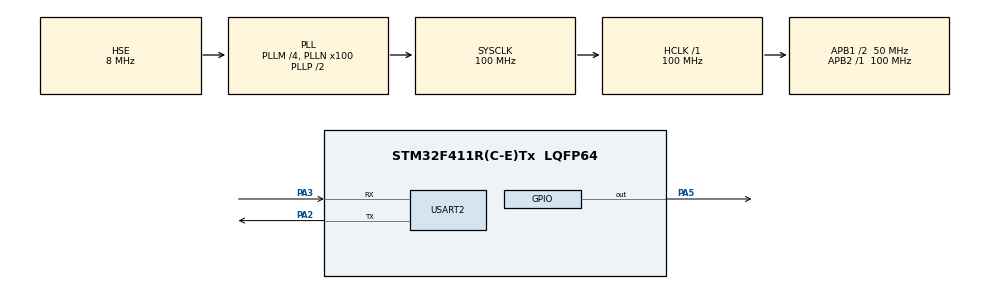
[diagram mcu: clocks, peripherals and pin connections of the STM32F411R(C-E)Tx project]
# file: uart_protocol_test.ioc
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Mcu.Family=STM32F4
Mcu.Name=STM32F411R(C-E)Tx
Mcu.Package=LQFP64
NVIC.PriorityGroup=NVIC_PRIORITYGROUP_4
NVIC.USART2_IRQn=true\:0\:0\:false\:false\:true\:true\:true\:true
PA13.Mode=Serial_Wire
PA13.Signal=SYS_JTMS-SWDIO
PA14.Mode=Serial_Wire
PA14.Signal=SYS_JTCK-SWCLK
PA2.Mode=Asynchronous
PA2.Signal=USART2_TX
PA3.Mode=Asynchronous
PA3.Signal=USART2_RX
PA5.Signal=GPIO_Output
PH0\ -\ OSC_IN.Mode=HSE-External-Oscillator
PH0\ -\ OSC_IN.Signal=RCC_OSC_IN
PH1\ -\ OSC_OUT.Mode=HSE-External-Oscillator
PH1\ -\ OSC_OUT.Signal=RCC_OSC_OUT
ProjectManager.HeapSize=0x200
ProjectManager.StackSize=0x400
ProjectManager.TargetToolchain=STM32CubeIDE
RCC.48MHZClocksFreq_Value=50000000
RCC.AHBFreq_Value=100000000
RCC.APB1CLKDivider=RCC_HCLK_DIV2
RCC.APB1Freq_Value=50000000
RCC.APB1TimFreq_Value=100000000
RCC.APB2Freq_Value=100000000
RCC.APB2TimFreq_Value=100000000
RCC.CortexFreq_Value=100000000
RCC.HCLKFreq_Value=100000000
RCC.HSE_VALUE=8000000
RCC.HSI_VALUE=16000000
RCC.LSE_VALUE=32768
RCC.PLLM=4
RCC.PLLN=100
RCC.PLLSourceVirtual=RCC_PLLSOURCE_HSE
RCC.SYSCLKFreq_VALUE=100000000
RCC.SYSCLKSource=RCC_SYSCLKSOURCE_PLLCLK
RCC.VCOOutputFreq_Value=200000000
USART2.VirtualMode=VM_ASYNC
board=custom

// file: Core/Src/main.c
/* USER CODE BEGIN Header */
/**
 ******************************************************************************
 * @file           : main.c
 * @brief          : Main program body
 ******************************************************************************
 */
/* USER CODE END Header */
#include "main.h"
#include "usart.h"
#include "gpio.h"

/* USER CODE BEGIN Includes */
#include <stdio.h>
#include <string.h> // memset 사용을 위해 추가
/* USER CODE END Includes */

/* USER CODE BEGIN PTD */

// 프로토콜 데이터 구조체 정의
typedef struct {
  uint8_t startByte1;
  uint8_t startByte2;
  uint8_t dataLength;
  uint8_t command;
  uint8_t objNum1;
  uint8_t objNum2;
  uint8_t dataByte;
  uint8_t data1;
  uint8_t data2;
} ProtocolData_t;

/* USER CODE END PTD */

/* USER CODE BEGIN PD */
#define START_BYTE1     0x5A
#define START_BYTE2     0xA5
#define DATA_LENGTH 9 // 수신 데이터 길이
/* USER CODE END PD */

/* USER CODE BEGIN PV */
uint8_t rxData;                  // 한 바이트 수신용 변수
uint8_t rxBuffer[DATA_LENGTH];   // 전체 데이터 저장 버퍼
uint8_t dataIndex = 0;           // 데이터 인덱스

ProtocolData_t protocolData; // 수신된 데이터를 저장할 구조체
/* USER CODE END PV */

void SystemClock_Config(void);

/* USER CODE BEGIN 0 */

/* UART2 수신 interrupt 핸들러 */
void HAL_UART_RxCpltCallback(UART_HandleTypeDef *huart)
{

  if (huart->Instance == USART2)
  {
    switch(dataIndex)
    {
      case 0:  // 첫 바이트
      if(rxData == START_BYTE1)
      {
        rxBuffer[dataIndex++] = rxData;
      }
      break;

      case 1:  // 두번째 바이트
        if(rxData == START_BYTE2)
        {
          rxBuffer[dataIndex++] = rxData;
        }
        else
        {
          dataIndex = 0;
        }
        break;

      default:  // 나머지 데이터
        rxBuffer[dataIndex++] = rxData;
        if(dataIndex >= DATA_LENGTH)
        {
          protocolData.startByte1 = rxBuffer[0];
          protocolData.startByte2 = rxBuffer[1];
          protocolData.dataLength = rxBuffer[2];
          protocolData.command = rxBuffer[3];
          protocolData.objNum1 = rxBuffer[4];
          protocolData.objNum2 = rxBuffer[5];
          protocolData.dataByte = rxBuffer[6];
          protocolData.data1 = rxBuffer[7];
          protocolData.data2 = rxBuffer[8];

          dataIndex = 0;
        }
        break;
    }

    // objNum1과 objNum2 값이 0x40, 0x00일 경우 LED 토글
    if (protocolData.objNum1 == 0x40 && protocolData.objNum2 == 0x00)
    {
      HAL_GPIO_TogglePin(GPIOA, GPIO_PIN_5); // PA5 LED 토글
    }

    HAL_UART_Receive_IT(&huart2, &rxData, 1);

  }

//
//
//
//
//  /* UART2에서 받은 데이터를 저장 */
//  if (huart->Instance == USART2)
//  {
//    rxBuffer[dataIndex++] = rxData; // 수신 데이터를 버퍼에 저장
//
//    // 데이터가 모두 수신되었는지 확인
//    if (dataIndex >= DATA_LENGTH)
//    {
//      dataIndex = 0; // 인덱스 초기화
//
//      // startByte1과 startByte2 값이 0x5A, 0xA5일 경우
//      if (rxBuffer[0] == 0x5A && rxBuffer[1] == 0xA5)
//      {
//        // 수신된 데이터를 구조체에 저장
//        memcpy(&protocolData, rxBuffer, sizeof(protocolData));
//
//
//        // objNum1과 objNum2 값이 0x40, 0x00일 경우 LED 토글
//        if (protocolData.objNum1 == 0x40 && protocolData.objNum2 == 0x00)
//        {
//          HAL_GPIO_TogglePin(GPIOA, GPIO_PIN_5); // PA5 LED 토글
//        }
//
//
//        // 버퍼 초기화
//        memset(rxBuffer, 0, DATA_LENGTH);
//      }
//
//      // 인터럽트 재설정
//      HAL_UART_Receive_IT(&huart2, &rxData, sizeof(rxData));
//      return; // startByte1, startByte2가 일치하면 바로 대기 상태로 나가도록 return
//    }

//    // 다음 데이터를 수신하도록 인터럽트 재설정
//    HAL_UART_Receive_IT(&huart2, &rxData, sizeof(rxData));
//  }
}
/* USER CODE END 0 */

int main(void)
{

  /* MCU Configuration--------------------------------------------------------*/

  /* Reset of all peripherals, Initializes the Flash interface and the Systick. */
  HAL_Init();

  /* Configure the system clock */
  SystemClock_Config();

  /* Initialize all configured peripherals */
  MX_GPIO_Init();
  MX_USART2_UART_Init();

  /* USER CODE BEGIN 2 */
  /* UART2 수신 인터럽트 활성화 */
  HAL_UART_Receive_IT(&huart2, &rxData, sizeof(rxData)); // 1 바이트 수신을 위한 인터럽트 설정
  /* USER CODE END 2 */

  /* Infinite loop */
  while (1)
  {

  }
}

void SystemClock_Config(void)
{
  RCC_OscInitTypeDef RCC_OscInitStruct = {0};
  RCC_ClkInitTypeDef RCC_ClkInitStruct = {0};

  /** Configure the main internal regulator output voltage
   */
  __HAL_RCC_PWR_CLK_ENABLE();
  __HAL_PWR_VOLTAGESCALING_CONFIG(PWR_REGULATOR_VOLTAGE_SCALE1);

  /** Initializes the RCC Oscillators according to the specified parameters
   * in the RCC_OscInitTypeDef structure.
   */
  RCC_OscInitStruct.OscillatorType = RCC_OSCILLATORTYPE_HSE;
  RCC_OscInitStruct.HSEState = RCC_HSE_ON;
  RCC_OscInitStruct.PLL.PLLState = RCC_PLL_ON;
  RCC_OscInitStruct.PLL.PLLSource = RCC_PLLSOURCE_HSE;
  RCC_OscInitStruct.PLL.PLLM = 4;
  RCC_OscInitStruct.PLL.PLLN = 100;
  RCC_OscInitStruct.PLL.PLLP = RCC_PLLP_DIV2;
  RCC_OscInitStruct.PLL.PLLQ = 4;
  if (HAL_RCC_OscConfig(&RCC_OscInitStruct) != HAL_OK)
  {
    Error_Handler();
  }

  /** Initializes the CPU, AHB and APB buses clocks
   */
  RCC_ClkInitStruct.ClockType = RCC_CLOCKTYPE_HCLK|RCC_CLOCKTYPE_SYSCLK
      |RCC_CLOCKTYPE_PCLK1|RCC_CLOCKTYPE_PCLK2;
  RCC_ClkInitStruct.SYSCLKSource = RCC_SYSCLKSOURCE_PLLCLK;
  RCC_ClkInitStruct.AHBCLKDivider = RCC_SYSCLK_DIV1;
  RCC_ClkInitStruct.APB1CLKDivider = RCC_HCLK_DIV2;
  RCC_ClkInitStruct.APB2CLKDivider = RCC_HCLK_DIV1;

  if (HAL_RCC_ClockConfig(&RCC_ClkInitStruct, FLASH_LATENCY_3) != HAL_OK)
  {
    Error_Handler();
  }
}

void Error_Handler(void)
{
  __disable_irq();
  while (1)
  {
  }
}
